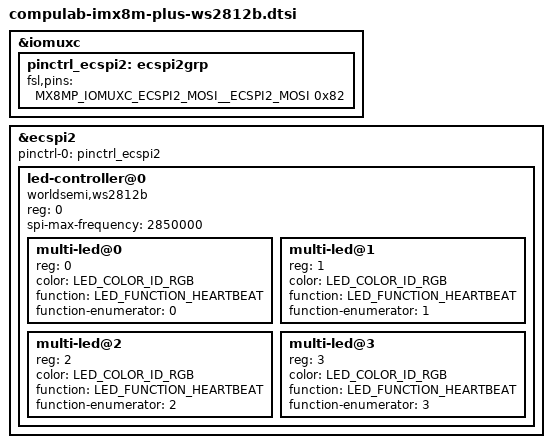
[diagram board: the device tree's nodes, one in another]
#include <dt-bindings/leds/common.h>

/* Sample device tree for connecting an RGB led strip to the SBEV board
 * Connectivity:
 * 5V0  P17.1
 * GRD  P17.8
 * MOSI P15.3
 */

&iomuxc {
	pinctrl_ecspi2: ecspi2grp {
		fsl,pins = <
			MX8MP_IOMUXC_ECSPI2_MOSI__ECSPI2_MOSI		0x82
		>;
	};
};

&ecspi2 {
	#address-cells = <1>;
	#size-cells = <0>;
	pinctrl-names = "default";
	pinctrl-0 = <&pinctrl_ecspi2>;
	status = "okay";

        led-controller@0 {
            compatible = "worldsemi,ws2812b";
            reg = <0>;
            #address-cells = <1>;
            #size-cells = <0>;
            spi-max-frequency = <2850000>;
            multi-led@0 {
                reg = <0>;
                color = <LED_COLOR_ID_RGB>;
                function = LED_FUNCTION_HEARTBEAT;
                function-enumerator = <0>;
            };
            multi-led@1 {
                reg = <1>;
                color = <LED_COLOR_ID_RGB>;
                function = LED_FUNCTION_HEARTBEAT;
                function-enumerator = <1>;
            };
            multi-led@2 {
                reg = <2>;
                color = <LED_COLOR_ID_RGB>;
                function = LED_FUNCTION_HEARTBEAT;
                function-enumerator = <2>;
            };
            multi-led@3 {
                reg = <3>;
                color = <LED_COLOR_ID_RGB>;
                function = LED_FUNCTION_HEARTBEAT;
                function-enumerator = <3>;
            };
        };
};
